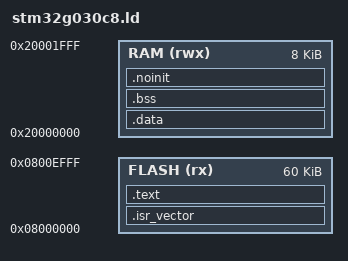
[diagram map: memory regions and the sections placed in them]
ENTRY(Reset_Handler)

MEMORY
{
    /* Pages 30 and 31 (0x0800F000..0x0800FFFF) are the settings journal. */
    FLASH (rx)  : ORIGIN = 0x08000000, LENGTH = 60K
    RAM   (rwx) : ORIGIN = 0x20000000, LENGTH = 8K
}

_estack = ORIGIN(RAM) + LENGTH(RAM);

SECTIONS
{
    .isr_vector :
    {
        . = ALIGN(4);
        KEEP(*(.isr_vector))
        . = ALIGN(4);
    } > FLASH

    .text :
    {
        . = ALIGN(4);
        *(.text*)
        *(.rodata*)
        . = ALIGN(4);
        _etext = .;
    } > FLASH

    .data : AT(_etext)
    {
        . = ALIGN(4);
        _sdata = .;
        *(.data*)
        . = ALIGN(4);
        _edata = .;
    } > RAM
    _sidata = LOADADDR(.data);

    .bss (NOLOAD) :
    {
        . = ALIGN(4);
        _sbss = .;
        *(.bss*)
        *(COMMON)
        . = ALIGN(4);
        _ebss = .;
    } > RAM

    .noinit (NOLOAD) :
    {
        . = ALIGN(4);
        *(.noinit*)
        . = ALIGN(4);
    } > RAM

    . = ALIGN(8);
    _end = .;

    /DISCARD/ :
    {
        *(.comment*)
        *(.note*)
    }

    ASSERT(_etext <= 0x0800F000, "firmware overlaps settings journal")
}
